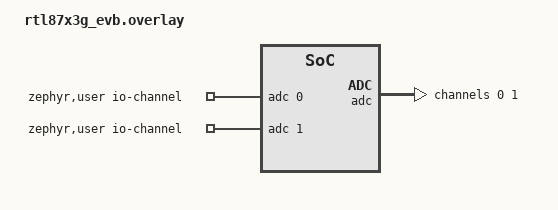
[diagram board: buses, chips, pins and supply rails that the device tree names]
/*
 * Copyright(c) 2025, Realtek Semiconductor Corporation.
 *
 * SPDX-License-Identifier: Apache-2.0
 */


/ {
    zephyr,user {
        io-channels = <&adc 0>, <&adc 1>;
    };
};
&adc {
    pinctrl-0 = <&adc_default>;
    pinctrl-names = "default";
    #address-cells = <1>;
    #size-cells = <0>;
    status = "okay";
    channel@0 {
        reg = <0>;
        zephyr,gain = "ADC_GAIN_1";
        zephyr,reference = "ADC_REF_INTERNAL";
        zephyr,acquisition-time = <ADC_ACQ_TIME_DEFAULT>;
        zephyr,resolution = <12>;
    };
    channel@1 {
        reg = <1>;
        zephyr,gain = "ADC_GAIN_1";
        zephyr,reference = "ADC_REF_INTERNAL";
        zephyr,acquisition-time = <ADC_ACQ_TIME_DEFAULT>;
        zephyr,resolution = <12>;
    };
};

&pinctrl {
    adc_default: adc_default {
        group1 {
            psels = <RTL87X3G_PSEL(SW_MODE, ADC_0, DIR_IN,DRV_LOW, PULL_NONE)>,
            <RTL87X3G_PSEL(SW_MODE, ADC_1, DIR_IN, DRV_LOW, PULL_NONE)>;
        };
    };
};

